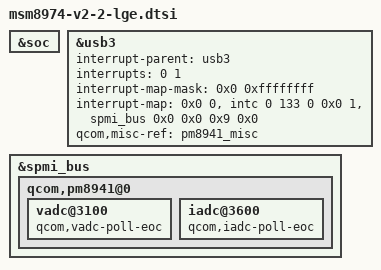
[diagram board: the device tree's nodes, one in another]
/* Copyright (c) 2012, Code Aurora Forum. All rights reserved.
 *
 * This program is free software; you can redistribute it and/or modify
 * it under the terms of the GNU General Public License version 2 and
 * only version 2 as published by the Free Software Foundation.
 *
 * This program is distributed in the hope that it will be useful,
 * but WITHOUT ANY WARRANTY; without even the implied warranty of
 * MERCHANTABILITY or FITNESS FOR A PARTICULAR PURPOSE.  See the
 * GNU General Public License for more details.
 */

/include/ "../msm8974-v2-2.dtsi"
/include/ "msm8974-lge-common.dtsi"

&soc {

};

&usb3 {
	interrupt-parent = <&usb3>;
	interrupts = <0 1>;
	#interrupt-cells = <1>;
	interrupt-map-mask = <0x0 0xffffffff>;
        interrupt-map = <0x0 0 &intc 0 133 0
                        0x0 1 &spmi_bus 0x0 0x0 0x9 0x0>;
        interrupt-names = "hs_phy_irq", "pmic_id_irq";

	qcom,misc-ref = <&pm8941_misc>;
};

/* At first, SPMI polling method is applied on MSM8974v2.2 only */
&spmi_bus {
	qcom,pm8941@0 {
		vadc@3100 {
			qcom,vadc-poll-eoc;
		};
		iadc@3600 {
			qcom,iadc-poll-eoc;
		};
	};
};
